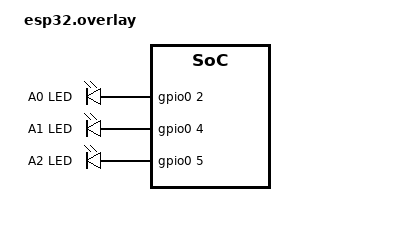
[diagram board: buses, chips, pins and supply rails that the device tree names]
/ {
	aliases {
		leda0 = &led0;
		leda1 = &led1;
		leda2 = &led2;
	};

	leds {
		compatible = "gpio-leds";

		led0: led_0 {
			gpios = <&gpio0 2 GPIO_ACTIVE_HIGH>;
			label = "A0 LED";
		};

		led1: led_1 {
			gpios = <&gpio0 4 GPIO_ACTIVE_HIGH>;
			label = "A1 LED";
		};

		led2: led_2 {
			gpios = <&gpio0 5 GPIO_ACTIVE_HIGH>;
			label = "A2 LED";
		};
	};
};
